AUTOSAR XML (schema 314)
package /ComponentType
  internal behavior Sa_DigColPs_InternalBehavior: component=Sa_DigColPs
    4 x timing event:
      DigColPs_Init1_InitEvent: start-on-event=DigColPs_Init1, period=0
      TMT_DigColPs_Per1: start-on-event=DigColPs_Per1, period=0.002
      TMT_DigColPs_Per2: start-on-event=DigColPs_Per2, period=0.004
      TMT_DigColPs_Per3: start-on-event=DigColPs_Per3, period=0.1
    4 x operation invoked event:
      OIT_DigColPs_SCom_CustClrTrim_DigColPs_SCom_CustClearTrim: start-on-event=DigColPs_SCom_CustClrTrim, operation=DigColPs_SCom.CustClearTrim
      OIT_DigColPs_SCom_CustSetTrim_DigColPs_SCom_CustSetTrim: start-on-event=DigColPs_SCom_CustSetTrim, operation=DigColPs_SCom.CustSetTrim
      OIT_DigColPs_SCom_NxtClrTrim_DigColPs_SCom_NxtClrTrim: start-on-event=DigColPs_SCom_NxtClrTrim, operation=DigColPs_SCom.NxtClrTrim
      OIT_DigColPs_SCom_NxtSetTrim_DigColPs_SCom_NxtSetTrim: start-on-event=DigColPs_SCom_NxtSetTrim, operation=DigColPs_SCom.NxtSetTrim
    per instance memory DigColPsEOL: type=DigColPsEOLType, type-definition=/DataType/DigColPsEOLType
    port-api-options:
      enable-take-address=false, indirect-api=false, port=DigColPs_SCom
      enable-take-address=false, indirect-api=false, port=EOLDigColPosCals
      enable-take-address=false, indirect-api=false, port=I2CHwAbsPos
      enable-take-address=false, indirect-api=false, port=I2CHwAbsPosValid
      enable-take-address=false, indirect-api=false, port=MecState
      enable-take-address=false, indirect-api=false, port=NxtrDiagMgr
      enable-take-address=false, indirect-api=false, port=SystemTime
      enable-take-address=false, indirect-api=false, port=TrimComp
    8 x runnable:
      DigColPs_Init1
        sync call SC_EOLDigColPosCals_WriteBlock: operation=EOLDigColPosCals.WriteBlock, timeout=0
      DigColPs_Per1
        sync call SC_NxtrDiagMgr_SetNTCStatus: operation=NxtrDiagMgr.SetNTCStatus, timeout=0
        sync call SC_SystemTime_DtrmnElapsedTime_mS_u16: operation=SystemTime.DtrmnElapsedTime_mS_u16, timeout=0
        sync call SC_SystemTime_GetSystemTime_mS_u32: operation=SystemTime.GetSystemTime_mS_u32, timeout=0
      DigColPs_Per2
        data read access READ_MecState_Cnt_enum: data-element=MecState.Cnt_enum
        data write access WRITE_I2CHwAbsPos_HwDeg_f32: data-element=I2CHwAbsPos.HwDeg_f32
        data write access WRITE_I2CHwAbsPosValid_Cnt_lgc: data-element=I2CHwAbsPosValid.Cnt_lgc
        data write access WRITE_TrimComp_Cnt_lgc: data-element=TrimComp.Cnt_lgc
        sync call SC_NxtrDiagMgr_GetNTCActive: operation=NxtrDiagMgr.GetNTCActive, timeout=0
        sync call SC_NxtrDiagMgr_SetNTCStatus: operation=NxtrDiagMgr.SetNTCStatus, timeout=0
      DigColPs_Per3
        sync call SC_NxtrDiagMgr_SetNTCStatus: operation=NxtrDiagMgr.SetNTCStatus, timeout=0
      DigColPs_SCom_CustClrTrim
        sync call SC_EOLDigColPosCals_WriteBlock: operation=EOLDigColPosCals.WriteBlock, timeout=0
      DigColPs_SCom_CustSetTrim
        sync call SC_EOLDigColPosCals_WriteBlock: operation=EOLDigColPosCals.WriteBlock, timeout=0
      DigColPs_SCom_NxtClrTrim
      DigColPs_SCom_NxtSetTrim
    service-needss:
      swc nv block needs DigColPosSnsrEOLBlk: n-data-sets=0, readonly=false, reliability=LOW, resistant-to-changed-sw=false, restore-at-start=false, write-only-once=false, writing-frequency=0, writing-priority=LOW, mirror-block=DigColPsEOL
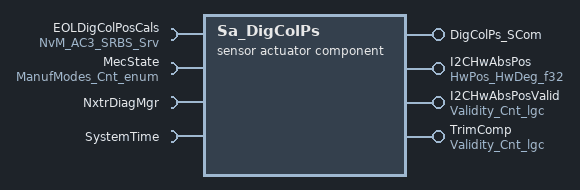
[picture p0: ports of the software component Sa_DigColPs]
  sensor actuator software component type Sa_DigColPs
    4 x provide port:
      DigColPs_SCom: provided-interface=DigColPs_SCom
        provided-com-specs:
          operation=CustClearTrim, queue-length=1
          operation=CustSetTrim, queue-length=1
          operation=NxtClrTrim, queue-length=1
          operation=NxtSetTrim, queue-length=1
      I2CHwAbsPos: unqueued-sender-com-spec{data-element=HwDeg_f32, can-invalidate=false, init-value=D_ZERO_ULS_F32}, provided-interface=HwPos_HwDeg_f32
      I2CHwAbsPosValid: unqueued-sender-com-spec{data-element=Cnt_lgc, can-invalidate=false, init-value=D_FALSE_CNT_LGC}, provided-interface=Validity_Cnt_lgc
      TrimComp: unqueued-sender-com-spec{data-element=Cnt_lgc, can-invalidate=false, init-value=D_FALSE_CNT_LGC}, provided-interface=Validity_Cnt_lgc
    4 x require port:
      EOLDigColPosCals: required-com-specs=[EraseBlock, GetErrorStatus, InvalidateNvBlock, ReadBlock, SetRamBlockStatus, WriteBlock], required-interface=NvM_AC3_SRBS_Srv
      MecState: unqueued-receiver-com-spec{data-element=Cnt_enum, init-value=D_MANUFMODEINIT_CNT_ENUM}, required-interface=ManufModes_Cnt_enum
      NxtrDiagMgr: required-com-specs=[GetNTCActive, GetNTCFailed, GetNTCStatus, SetNTCStatus], required-interface=NxtrDiagMgr
      SystemTime: required-interface=SystemTime
        required-com-specs:
          DtrmnElapsedTime_mS_u16
          DtrmnElapsedTime_mS_u32
          DtrmnElapsedTime_uS_u16
          DtrmnElapsedTime_uS_u32
          GetSystemTime_mS_u32
          GetSystemTime_uS_u32
  swc implementation Sa_DigColPs_Implementation: behavior=Sa_DigColPs_InternalBehavior
    code-descriptors:
      code Code: type=SRC
